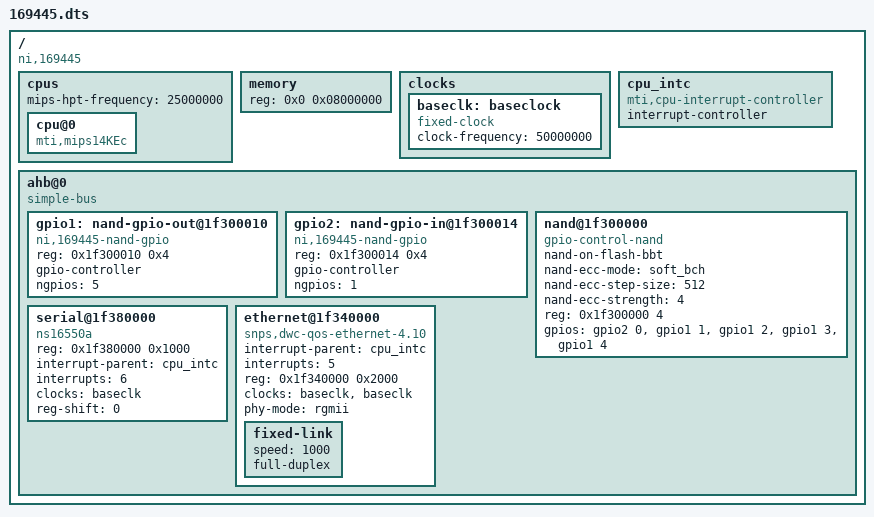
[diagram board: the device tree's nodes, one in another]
/dts-v1/;

/ {
	#address-cells = <1>;
	#size-cells = <1>;
	compatible = "ni,169445";

	cpus {
		mips-hpt-frequency = <25000000>;

		cpu@0 {
			compatible = "mti,mips14KEc";
		};
	};

	memory {
		device_type = "memory";
		reg = <0x0 0x08000000>;
	};

	clocks {
		baseclk: baseclock {
			compatible = "fixed-clock";
			#clock-cells = <0>;
			clock-frequency = <50000000>;
		};
	};

	cpu_intc: cpu_intc {
		#address-cells = <0>;
		compatible = "mti,cpu-interrupt-controller";
		interrupt-controller;
		#interrupt-cells = <1>;
	};

	ahb@0 {
		compatible = "simple-bus";
		#address-cells = <1>;
		#size-cells = <1>;
		ranges;

		gpio1: nand-gpio-out@1f300010 {
			compatible = "ni,169445-nand-gpio";
			reg = <0x1f300010 0x4>;
			reg-names = "dat";
			gpio-controller;
			#gpio-cells = <2>;
			ngpios = <5>;
		};

		gpio2: nand-gpio-in@1f300014 {
			compatible = "ni,169445-nand-gpio";
			reg = <0x1f300014 0x4>;
			reg-names = "dat";
			gpio-controller;
			#gpio-cells = <2>;
			ngpios = <1>;
		};

		nand@1f300000 {
			compatible = "gpio-control-nand";
			nand-on-flash-bbt;
			nand-ecc-mode = "soft_bch";
			nand-ecc-step-size = <512>;
			nand-ecc-strength = <4>;
			reg = <0x1f300000 4>;
			gpios = <&gpio2 0 0>, /* rdy */
				<&gpio1 1 0>, /* nce */
				<&gpio1 2 0>, /* ale */
				<&gpio1 3 0>, /* cle */
				<&gpio1 4 0>; /* nwp */
		};

		serial@1f380000 {
			compatible = "ns16550a";
			reg = <0x1f380000 0x1000>;
			interrupt-parent = <&cpu_intc>;
			interrupts = <6>;
			clocks = <&baseclk>;
			reg-shift = <0>;
		};

		ethernet@1f340000 {
			compatible = "snps,dwc-qos-ethernet-4.10";
			interrupt-parent = <&cpu_intc>;
			interrupts = <5>;
			reg = <0x1f340000 0x2000>;
			clock-names = "apb_pclk", "phy_ref_clk";
			clocks = <&baseclk>, <&baseclk>;

			phy-mode = "rgmii";

			fixed-link {
				speed = <1000>;
				full-duplex;
			};
		};
	};
};
